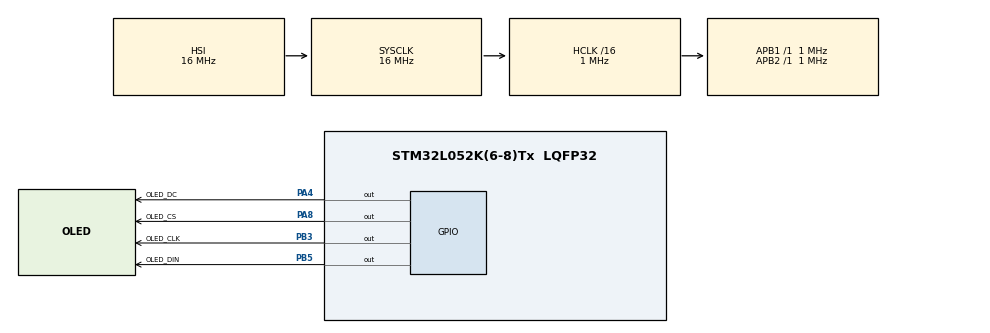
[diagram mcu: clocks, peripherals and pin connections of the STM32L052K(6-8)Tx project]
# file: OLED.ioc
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Mcu.Family=STM32L0
RCC.MSI_VALUE=2097000
VP_TIM6_VS_ClockSourceINT.Mode=Enable_Timer
RCC.SYSCLKSource=RCC_SYSCLKSOURCE_HSI
ProjectManager.StackSize=0x400
PA13.Signal=SYS_SWDIO
RCC.HSI16_VALUE=16000000
PA8.GPIO_Label=OLED_CS
ProjectManager.TargetToolchain=MDK-ARM V5.27
RCC.HCLKFreq_Value=1000000
RCC.APB2TimFreq_Value=1000000
RCC.LSE_VALUE=32768
RCC.AHBFreq_Value=1000000
board=custom
RCC.VCOOutputFreq_Value=48000000
RCC.APB2Freq_Value=1000000
PA14.Mode=Serial_Wire
PA8.Signal=GPIO_Output
RCC.AHBCLKDivider=RCC_SYSCLK_DIV16
PA13.Mode=Serial_Wire
Mcu.Name=STM32L052K(6-8)Tx
PB3.Signal=GPIO_Output
PA4.Signal=GPIO_Output
RCC.SYSCLKFreq_VALUE=16000000
Mcu.Package=LQFP32
PB5.Signal=GPIO_Output
PA14.Signal=SYS_SWCLK
ProjectManager.HeapSize=0x200
RCC.HSI_VALUE=16000000
PB5.GPIO_Label=OLED_DIN
RCC.APB1TimFreq_Value=1000000
RCC.APB1Freq_Value=1000000
PA4.GPIO_Label=OLED_DC
RCC.HSI48_VALUE=48000000
PB3.GPIO_Label=OLED_CLK

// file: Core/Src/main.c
/* USER CODE BEGIN Header */
/**
  ******************************************************************************
  * @file           : main.c
  * @brief          : Main program body
  ******************************************************************************
  * @attention
  *
  * <h2><center>&copy; Copyright (c) 2023 STMicroelectronics.
  * All rights reserved.</center></h2>
  *
  * This software component is licensed by ST under BSD 3-Clause license,
  * the "License"; You may not use this file except in compliance with the
  * License. You may obtain a copy of the License at:
  *                        opensource.org/licenses/BSD-3-Clause
  *
  ******************************************************************************
  */
/* USER CODE END Header */
#include "main.h"

/* USER CODE BEGIN Includes */
#include "OLED.h"
#include "ssd1306_fonts.h"
/* USER CODE END Includes */

TIM_HandleTypeDef htim6;

void SystemClock_Config(void);
static void MX_GPIO_Init(void);
static void MX_TIM6_Init(void);

int main(void)
{

  /* MCU Configuration--------------------------------------------------------*/

  /* Reset of all peripherals, Initializes the Flash interface and the Systick. */
  HAL_Init();

  /* Configure the system clock */
  SystemClock_Config();

  /* Initialize all configured peripherals */
  MX_GPIO_Init();
  MX_TIM6_Init();
  /* USER CODE BEGIN 2 */
	oled_init();
	oled_str("You're looking at an OLED\npanel.", 0, 0, ssd1306xled_font8x16);

	oled_RefreshGram();
  /* USER CODE END 2 */

  /* Infinite loop */
  while (1)
  {

  }
}

void SystemClock_Config(void)
{
  RCC_OscInitTypeDef RCC_OscInitStruct = {0};
  RCC_ClkInitTypeDef RCC_ClkInitStruct = {0};

  /** Configure the main internal regulator output voltage
  */
  __HAL_PWR_VOLTAGESCALING_CONFIG(PWR_REGULATOR_VOLTAGE_SCALE1);
  /** Initializes the RCC Oscillators according to the specified parameters
  * in the RCC_OscInitTypeDef structure.
  */
  RCC_OscInitStruct.OscillatorType = RCC_OSCILLATORTYPE_HSI;
  RCC_OscInitStruct.HSIState = RCC_HSI_ON;
  RCC_OscInitStruct.HSICalibrationValue = RCC_HSICALIBRATION_DEFAULT;
  RCC_OscInitStruct.PLL.PLLState = RCC_PLL_NONE;
  if (HAL_RCC_OscConfig(&RCC_OscInitStruct) != HAL_OK)
  {
    Error_Handler();
  }
  /** Initializes the CPU, AHB and APB buses clocks
  */
  RCC_ClkInitStruct.ClockType = RCC_CLOCKTYPE_HCLK|RCC_CLOCKTYPE_SYSCLK
                              |RCC_CLOCKTYPE_PCLK1|RCC_CLOCKTYPE_PCLK2;
  RCC_ClkInitStruct.SYSCLKSource = RCC_SYSCLKSOURCE_HSI;
  RCC_ClkInitStruct.AHBCLKDivider = RCC_SYSCLK_DIV16;
  RCC_ClkInitStruct.APB1CLKDivider = RCC_HCLK_DIV1;
  RCC_ClkInitStruct.APB2CLKDivider = RCC_HCLK_DIV1;

  if (HAL_RCC_ClockConfig(&RCC_ClkInitStruct, FLASH_LATENCY_0) != HAL_OK)
  {
    Error_Handler();
  }
}

static void MX_TIM6_Init(void)
{

  TIM_MasterConfigTypeDef sMasterConfig = {0};

  htim6.Instance = TIM6;
  htim6.Init.Prescaler = 0;
  htim6.Init.CounterMode = TIM_COUNTERMODE_UP;
  htim6.Init.Period = 65535;
  htim6.Init.AutoReloadPreload = TIM_AUTORELOAD_PRELOAD_DISABLE;
  if (HAL_TIM_Base_Init(&htim6) != HAL_OK)
  {
    Error_Handler();
  }
  sMasterConfig.MasterOutputTrigger = TIM_TRGO_RESET;
  sMasterConfig.MasterSlaveMode = TIM_MASTERSLAVEMODE_DISABLE;
  if (HAL_TIMEx_MasterConfigSynchronization(&htim6, &sMasterConfig) != HAL_OK)
  {
    Error_Handler();
  }

}

static void MX_GPIO_Init(void)
{
  GPIO_InitTypeDef GPIO_InitStruct = {0};

  /* GPIO Ports Clock Enable */
  __HAL_RCC_GPIOA_CLK_ENABLE();
  __HAL_RCC_GPIOB_CLK_ENABLE();

  /*Configure GPIO pin Output Level */
  HAL_GPIO_WritePin(GPIOA, OLED_DC_Pin|OLED_CS_Pin, GPIO_PIN_RESET);

  /*Configure GPIO pin Output Level */
  HAL_GPIO_WritePin(GPIOB, OLED_CLK_Pin|OLED_DIN_Pin, GPIO_PIN_RESET);

  /*Configure GPIO pins : OLED_DC_Pin OLED_CS_Pin */
  GPIO_InitStruct.Pin = OLED_DC_Pin|OLED_CS_Pin;
  GPIO_InitStruct.Mode = GPIO_MODE_OUTPUT_PP;
  GPIO_InitStruct.Pull = GPIO_NOPULL;
  GPIO_InitStruct.Speed = GPIO_SPEED_FREQ_LOW;
  HAL_GPIO_Init(GPIOA, &GPIO_InitStruct);

  /*Configure GPIO pins : OLED_CLK_Pin OLED_DIN_Pin */
  GPIO_InitStruct.Pin = OLED_CLK_Pin|OLED_DIN_Pin;
  GPIO_InitStruct.Mode = GPIO_MODE_OUTPUT_PP;
  GPIO_InitStruct.Pull = GPIO_NOPULL;
  GPIO_InitStruct.Speed = GPIO_SPEED_FREQ_LOW;
  HAL_GPIO_Init(GPIOB, &GPIO_InitStruct);

}

void Error_Handler(void)
{
}

/************************ (C) COPYRIGHT STMicroelectronics *****END OF FILE****/
